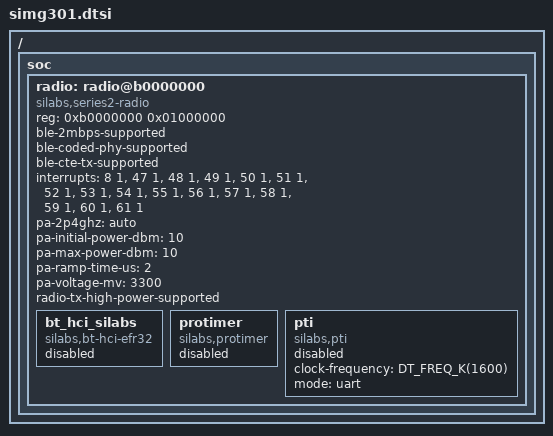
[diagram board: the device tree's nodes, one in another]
/*
 * Copyright (c) 2026 Silicon Laboratories Inc.
 *
 * SPDX-License-Identifier: Apache-2.0
 */

#include <silabs/six301/six301.dtsi>

/ {
	soc {
		radio: radio@b0000000 {
			compatible = "silabs,series2-radio";
			reg = <0xb0000000 0x01000000>;
			ble-2mbps-supported;
			ble-coded-phy-supported;
			ble-cte-tx-supported;
			interrupt-names = "sysmblpw0cpu", "bufc", "frc_pri", "frc", "protimer",
					  "rac_rsm", "rac_seq", "synth", "rfeca0", "rfeca1",
					  "modem", "agc", "rftimer", "seqacc", "hfrcolpw",
					  "hfrcodplllpw";
			interrupts = <8 1>, <47 1>, <48 1>, <49 1>, <50 1>, <51 1>, <52 1>, <53 1>,
				     <54 1>, <55 1>, <56 1>, <57 1>, <58 1>, <59 1>, <60 1>,
				     <61 1>;
			pa-2p4ghz = "auto";
			pa-initial-power-dbm = <10>;
			pa-max-power-dbm = <10>;
			pa-ramp-time-us = <2>;
			pa-voltage-mv = <3300>;
			radio-tx-high-power-supported;

			bt_hci_silabs: bt_hci_silabs {
				compatible = "silabs,bt-hci-efr32";
				status = "disabled";
			};

			protimer: protimer {
				compatible = "silabs,protimer";
				status = "disabled";
			};

			pti: pti {
				compatible = "silabs,pti";
				clock-frequency = <DT_FREQ_K(1600)>;
				mode = "uart";
				status = "disabled";
			};
		};
	};
};
